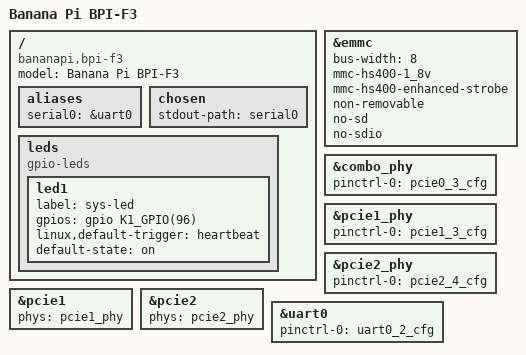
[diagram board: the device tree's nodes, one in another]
// SPDX-License-Identifier: GPL-2.0 OR MIT
/*
 * Copyright (C) 2024 Yangyu Chen <cyy@cyyself.name>
 */

#include "k1.dtsi"
#include "k1-pinctrl.dtsi"

/ {
	model = "Banana Pi BPI-F3";
	compatible = "bananapi,bpi-f3", "spacemit,k1";

	aliases {
		serial0 = &uart0;
	};

	chosen {
		stdout-path = "serial0";
	};

	leds {
		compatible = "gpio-leds";

		led1 {
			label = "sys-led";
			gpios = <&gpio K1_GPIO(96) GPIO_ACTIVE_HIGH>;
			linux,default-trigger = "heartbeat";
			default-state = "on";
		};
	};
};

&emmc {
	bus-width = <8>;
	mmc-hs400-1_8v;
	mmc-hs400-enhanced-strobe;
	non-removable;
	no-sd;
	no-sdio;
	status = "okay";
};

&combo_phy {
	pinctrl-names = "default";
	pinctrl-0 = <&pcie0_3_cfg>;
	status = "okay";
};

&pcie1_phy {
	pinctrl-names = "default";
	pinctrl-0 = <&pcie1_3_cfg>;
	status = "okay";
};

&pcie2_phy {
	pinctrl-names = "default";
	pinctrl-0 = <&pcie2_4_cfg>;
	status = "okay";
};

&pcie1 {
	phys = <&pcie1_phy>;
	status = "okay";
};

&pcie2 {
	phys = <&pcie2_phy>;
	status = "okay";
};

&uart0 {
	pinctrl-names = "default";
	pinctrl-0 = <&uart0_2_cfg>;
	status = "okay";
};
